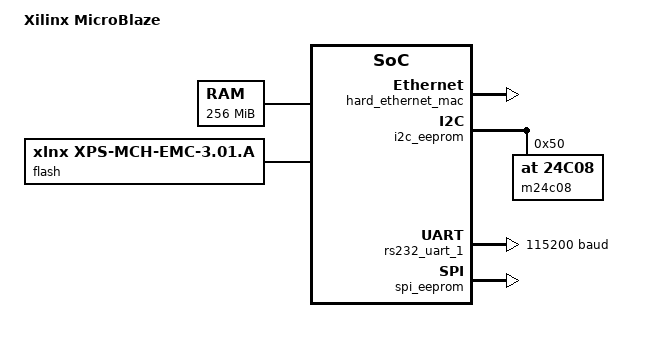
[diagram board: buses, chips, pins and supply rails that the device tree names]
/*
 * Device Tree Generator version: 1.3
 *
 * (C) Copyright 2007-2008 Xilinx, Inc.
 * (C) Copyright 2007-2009 Michal Simek
 *
 * Michal SIMEK <monstr@monstr.eu>
 *
 * This program is free software; you can redistribute it and/or
 * modify it under the terms of the GNU General Public License as
 * published by the Free Software Foundation; either version 2 of
 * the License, or (at your option) any later version.
 *
 * This program is distributed in the hope that it will be useful,
 * but WITHOUT ANY WARRANTY; without even the implied warranty of
 * MERCHANTABILITY or FITNESS FOR A PARTICULAR PURPOSE. See the
 * GNU General Public License for more details.
 *
 * You should have received a copy of the GNU General Public License
 * along with this program; if not, write to the Free Software
 * Foundation, Inc., 59 Temple Place, Suite 330, Boston,
 * MA 02111-1307 USA
 *
 * CAUTION: This file is automatically generated by libgen.
 * Version: Xilinx EDK 14.6 EDK_P.68d
 *
 * XPS project directory: linux_bsp_0
 */

/dts-v1/;
/ {
	#address-cells = <1>;
	#size-cells = <1>;
	compatible = "xlnx,microblaze";
	model = "Xilinx MicroBlaze";
	aliases {
		ethernet0 = &hard_ethernet_mac;
		serial0 = &rs232_uart_1;
	} ;
	chosen {
		bootargs = "console=ttyUL0 root=/dev/ram ip=10.1.7.250:10.1.7.125:10.1.7.2:255.255.255.0:ml505_linux:eth0
		rw mtdparts=82000000.flash:4M(bits),5M(zImage),22M(rootfs),896k(unused),128k(loader)";
		linux,stdout-path = "/plb@0/serial@81401000";
	} ;
	cpus {
		#address-cells = <1>;
		#cpus = <0x1>;
		#size-cells = <0>;
		microblaze_0: cpu@0 {
			clock-frequency = <100000000>;
			compatible = "xlnx,microblaze-8.50.b";
			d-cache-baseaddr = <0xc0000000>;
			d-cache-highaddr = <0xcfffffff>;
			d-cache-line-size = <0x10>;
			d-cache-size = <0x1000>;
			device_type = "cpu";
			i-cache-baseaddr = <0xc0000000>;
			i-cache-highaddr = <0xcfffffff>;
			i-cache-line-size = <0x10>;
			i-cache-size = <0x1000>;
			model = "microblaze,8.50.b";
			reg = <0>;
			timebase-frequency = <100000000>;
			xlnx,addr-tag-bits = <0x10>;
			xlnx,allow-dcache-wr = <0x1>;
			xlnx,allow-icache-wr = <0x1>;
			xlnx,area-optimized = <0x0>;
			xlnx,avoid-primitives = <0x0>;
			xlnx,base-vectors = <0x0>;
			xlnx,branch-target-cache-size = <0x0>;
			xlnx,cache-byte-size = <0x1000>;
			xlnx,d-axi = <0x0>;
			xlnx,d-lmb = <0x1>;
			xlnx,d-plb = <0x1>;
			xlnx,data-size = <0x20>;
			xlnx,dcache-addr-tag = <0x10>;
			xlnx,dcache-always-used = <0x1>;
			xlnx,dcache-byte-size = <0x1000>;
			xlnx,dcache-data-width = <0x0>;
			xlnx,dcache-force-tag-lutram = <0x0>;
			xlnx,dcache-interface = <0x0>;
			xlnx,dcache-line-len = <0x4>;
			xlnx,dcache-use-fsl = <0x1>;
			xlnx,dcache-use-writeback = <0x0>;
			xlnx,dcache-victims = <0x0>;
			xlnx,debug-enabled = <0x1>;
			xlnx,div-zero-exception = <0x1>;
			xlnx,dynamic-bus-sizing = <0x1>;
			xlnx,ecc-use-ce-exception = <0x0>;
			xlnx,edge-is-positive = <0x1>;
			xlnx,endianness = <0x0>;
			xlnx,family = "virtex5";
			xlnx,fault-tolerant = <0x0>;
			xlnx,fpu-exception = <0x0>;
			xlnx,freq = <0x5f5e100>;
			xlnx,fsl-data-size = <0x20>;
			xlnx,fsl-exception = <0x0>;
			xlnx,fsl-links = <0x0>;
			xlnx,i-axi = <0x0>;
			xlnx,i-lmb = <0x1>;
			xlnx,i-plb = <0x1>;
			xlnx,icache-always-used = <0x1>;
			xlnx,icache-data-width = <0x0>;
			xlnx,icache-force-tag-lutram = <0x0>;
			xlnx,icache-interface = <0x0>;
			xlnx,icache-line-len = <0x4>;
			xlnx,icache-streams = <0x1>;
			xlnx,icache-use-fsl = <0x1>;
			xlnx,icache-victims = <0x4>;
			xlnx,ill-opcode-exception = <0x1>;
			xlnx,instance = "microblaze_0";
			xlnx,interconnect = <0x1>;
			xlnx,interrupt-is-edge = <0x0>;
			xlnx,lockstep-slave = <0x0>;
			xlnx,mmu-dtlb-size = <0x4>;
			xlnx,mmu-itlb-size = <0x2>;
			xlnx,mmu-privileged-instr = <0x0>;
			xlnx,mmu-tlb-access = <0x3>;
			xlnx,mmu-zones = <0x2>;
			xlnx,number-of-pc-brk = <0x1>;
			xlnx,number-of-rd-addr-brk = <0x0>;
			xlnx,number-of-wr-addr-brk = <0x0>;
			xlnx,opcode-0x0-illegal = <0x1>;
			xlnx,optimization = <0x0>;
			xlnx,pc-width = <0x20>;
			xlnx,pvr = <0x2>;
			xlnx,pvr-user1 = <0x0>;
			xlnx,pvr-user2 = <0x0>;
			xlnx,reset-msr = <0x0>;
			xlnx,sco = <0x0>;
			xlnx,stream-interconnect = <0x0>;
			xlnx,unaligned-exceptions = <0x1>;
			xlnx,use-barrel = <0x1>;
			xlnx,use-branch-target-cache = <0x0>;
			xlnx,use-dcache = <0x1>;
			xlnx,use-div = <0x1>;
			xlnx,use-ext-brk = <0x1>;
			xlnx,use-ext-nm-brk = <0x1>;
			xlnx,use-extended-fsl-instr = <0x0>;
			xlnx,use-fpu = <0x0>;
			xlnx,use-hw-mul = <0x2>;
			xlnx,use-icache = <0x1>;
			xlnx,use-interrupt = <0x1>;
			xlnx,use-mmu = <0x3>;
			xlnx,use-msr-instr = <0x1>;
			xlnx,use-pcmp-instr = <0x1>;
			xlnx,use-reorder-instr = <0x1>;
			xlnx,use-stack-protection = <0x0>;
		} ;
	} ;
	ddr2_sdram: memory@c0000000 {
		device_type = "memory";
		reg = < 0xc0000000 0x10000000 >;
	} ;
	mb_plb: plb@0 {
		#address-cells = <1>;
		#size-cells = <1>;
		compatible = "xlnx,plb-v46-1.05.a", "xlnx,plb-v46-1.00.a", "simple-bus";
		ranges ;
		buttons_5bit: gpio@81404000 {
			compatible = "xlnx,xps-gpio-2.00.a", "xlnx,xps-gpio-1.00.a";
			interrupt-parent = <&xps_intc_0>;
			interrupts = < 11 2 >;
			reg = < 0x81404000 0x200 >;
			xlnx,all-inputs = <0x1>;
			xlnx,all-inputs-2 = <0x0>;
			xlnx,dout-default = <0x0>;
			xlnx,dout-default-2 = <0x0>;
			xlnx,family = "virtex5";
			xlnx,gpio-width = <0x5>;
			xlnx,gpio2-width = <0x20>;
			xlnx,interrupt-present = <0x1>;
			xlnx,is-dual = <0x0>;
			xlnx,tri-default = <0xffffffff>;
			xlnx,tri-default-2 = <0xffffffff>;
		} ;
		flash: flash@82000000 {
			bank-width = <2>;
			compatible = "xlnx,xps-mch-emc-3.01.a", "cfi-flash";
			reg = < 0x82000000 0x2000000 >;
			xlnx,family = "virtex5";
			xlnx,include-datawidth-matching-0 = <0x1>;
			xlnx,include-datawidth-matching-1 = <0x0>;
			xlnx,include-datawidth-matching-2 = <0x0>;
			xlnx,include-datawidth-matching-3 = <0x0>;
			xlnx,include-negedge-ioregs = <0x0>;
			xlnx,include-plb-ipif = <0x1>;
			xlnx,include-wrbuf = <0x1>;
			xlnx,max-mem-width = <0x10>;
			xlnx,mch-native-dwidth = <0x20>;
			xlnx,mch-splb-awidth = <0x20>;
			xlnx,mch-splb-clk-period-ps = <0x2710>;
			xlnx,mch0-accessbuf-depth = <0x10>;
			xlnx,mch0-protocol = <0x0>;
			xlnx,mch0-rddatabuf-depth = <0x10>;
			xlnx,mch1-accessbuf-depth = <0x10>;
			xlnx,mch1-protocol = <0x0>;
			xlnx,mch1-rddatabuf-depth = <0x10>;
			xlnx,mch2-accessbuf-depth = <0x10>;
			xlnx,mch2-protocol = <0x0>;
			xlnx,mch2-rddatabuf-depth = <0x10>;
			xlnx,mch3-accessbuf-depth = <0x10>;
			xlnx,mch3-protocol = <0x0>;
			xlnx,mch3-rddatabuf-depth = <0x10>;
			xlnx,mem0-width = <0x10>;
			xlnx,mem1-width = <0x20>;
			xlnx,mem2-width = <0x20>;
			xlnx,mem3-width = <0x20>;
			xlnx,num-banks-mem = <0x1>;
			xlnx,num-channels = <0x0>;
			xlnx,pagemode-flash-0 = <0x0>;
			xlnx,pagemode-flash-1 = <0x0>;
			xlnx,pagemode-flash-2 = <0x0>;
			xlnx,pagemode-flash-3 = <0x0>;
			xlnx,priority-mode = <0x0>;
			xlnx,synch-mem-0 = <0x0>;
			xlnx,synch-mem-1 = <0x0>;
			xlnx,synch-mem-2 = <0x0>;
			xlnx,synch-mem-3 = <0x0>;
			xlnx,synch-pipedelay-0 = <0x2>;
			xlnx,synch-pipedelay-1 = <0x2>;
			xlnx,synch-pipedelay-2 = <0x2>;
			xlnx,synch-pipedelay-3 = <0x2>;
			xlnx,tavdv-ps-mem-0 = <0x1adb0>;
			xlnx,tavdv-ps-mem-1 = <0x3a98>;
			xlnx,tavdv-ps-mem-2 = <0x3a98>;
			xlnx,tavdv-ps-mem-3 = <0x3a98>;
			xlnx,tcedv-ps-mem-0 = <0x1adb0>;
			xlnx,tcedv-ps-mem-1 = <0x3a98>;
			xlnx,tcedv-ps-mem-2 = <0x3a98>;
			xlnx,tcedv-ps-mem-3 = <0x3a98>;
			xlnx,thzce-ps-mem-0 = <0x88b8>;
			xlnx,thzce-ps-mem-1 = <0x1b58>;
			xlnx,thzce-ps-mem-2 = <0x1b58>;
			xlnx,thzce-ps-mem-3 = <0x1b58>;
			xlnx,thzoe-ps-mem-0 = <0x1b58>;
			xlnx,thzoe-ps-mem-1 = <0x1b58>;
			xlnx,thzoe-ps-mem-2 = <0x1b58>;
			xlnx,thzoe-ps-mem-3 = <0x1b58>;
			xlnx,tlzwe-ps-mem-0 = <0x88b8>;
			xlnx,tlzwe-ps-mem-1 = <0x0>;
			xlnx,tlzwe-ps-mem-2 = <0x0>;
			xlnx,tlzwe-ps-mem-3 = <0x0>;
			xlnx,tpacc-ps-flash-0 = <0x61a8>;
			xlnx,tpacc-ps-flash-1 = <0x61a8>;
			xlnx,tpacc-ps-flash-2 = <0x61a8>;
			xlnx,tpacc-ps-flash-3 = <0x61a8>;
			xlnx,twc-ps-mem-0 = <0x2af8>;
			xlnx,twc-ps-mem-1 = <0x3a98>;
			xlnx,twc-ps-mem-2 = <0x3a98>;
			xlnx,twc-ps-mem-3 = <0x3a98>;
			xlnx,twp-ps-mem-0 = <0x11170>;
			xlnx,twp-ps-mem-1 = <0x2ee0>;
			xlnx,twp-ps-mem-2 = <0x2ee0>;
			xlnx,twp-ps-mem-3 = <0x2ee0>;
			xlnx,xcl0-linesize = <0x4>;
			xlnx,xcl0-writexfer = <0x1>;
			xlnx,xcl1-linesize = <0x4>;
			xlnx,xcl1-writexfer = <0x1>;
			xlnx,xcl2-linesize = <0x4>;
			xlnx,xcl2-writexfer = <0x1>;
			xlnx,xcl3-linesize = <0x4>;
			xlnx,xcl3-writexfer = <0x1>;
		} ;
		hard_ethernet_mac: xps-ll-temac@81500000 {
			#address-cells = <1>;
			#size-cells = <1>;
			compatible = "xlnx,compound";
			ranges ;
			ethernet@81500000 {
				compatible = "xlnx,xps-ll-temac-2.03.a", "xlnx,xps-ll-temac-1.00.a";
				device_type = "network";
				interrupt-parent = <&xps_intc_0>;
				interrupts = < 9 2 >;
				llink-connected = <&PIM2>;
				local-mac-address = [ 00 0a 35 35 7b 00 ];
				reg = < 0x81500000 0x40 >;
				xlnx,avb = <0x0>;
				xlnx,bus2core-clk-ratio = <0x1>;
				xlnx,mcast-extend = <0x0>;
				xlnx,phy-type = <0x1>;
				xlnx,phyaddr = <0x1>;
				xlnx,rxcsum = <0x0>;
				xlnx,rxfifo = <0x1000>;
				xlnx,rxvlan-strp = <0x0>;
				xlnx,rxvlan-tag = <0x0>;
				xlnx,rxvlan-tran = <0x0>;
				xlnx,stats = <0x0>;
				xlnx,temac-type = <0x0>;
				xlnx,txcsum = <0x0>;
				xlnx,txfifo = <0x1000>;
				xlnx,txvlan-strp = <0x0>;
				xlnx,txvlan-tag = <0x0>;
				xlnx,txvlan-tran = <0x0>;
			} ;
		} ;
		i2c_eeprom: i2c@81406000 {
			compatible = "xlnx,xps-iic-2.03.a", "xlnx,xps-iic-2.00.a";
			interrupt-parent = <&xps_intc_0>;
			interrupts = < 10 2 >;
			reg = < 0x81406000 0x200 >;
			xlnx,clk-freq = <0x5f5e100>;
			xlnx,family = "virtex5";
			xlnx,gpo-width = <0x1>;
			xlnx,iic-freq = <0x186a0>;
			xlnx,scl-inertial-delay = <0x0>;
			xlnx,sda-inertial-delay = <0x0>;
			xlnx,ten-bit-adr = <0x0>;

      #address-cells = <1>;
      #size-cells = <0>;
      m24c08@50 {
          compatible = "at,24c08";
          reg = <0x50>;
      };
		} ;
		leds_8bit: gpio@81405000 {
			compatible = "xlnx,xps-gpio-2.00.a", "xlnx,xps-gpio-1.00.a";
			reg = < 0x81405000 0x200 >;
			xlnx,all-inputs = <0x0>;
			xlnx,all-inputs-2 = <0x0>;
			xlnx,dout-default = <0x0>;
			xlnx,dout-default-2 = <0x0>;
			xlnx,family = "virtex5";
			xlnx,gpio-width = <0x8>;
			xlnx,gpio2-width = <0x20>;
			xlnx,interrupt-present = <0x0>;
			xlnx,is-dual = <0x0>;
			xlnx,tri-default = <0xffffffff>;
			xlnx,tri-default-2 = <0xffffffff>;
		} ;
		mdm_0: debug@81408000 {
			compatible = "xlnx,mdm-2.10.a";
			reg = < 0x81408000 0x200 >;
			xlnx,family = "virtex5";
			xlnx,interconnect = <0x1>;
			xlnx,jtag-chain = <0x2>;
			xlnx,mb-dbg-ports = <0x1>;
			xlnx,use-bscan = <0x0>;
			xlnx,use-uart = <0x1>;
		} ;
		mpmc@c0000000 {
			#address-cells = <1>;
			#size-cells = <1>;
			compatible = "xlnx,mpmc-6.06.a";
			ranges ;
			PIM2: sdma@81410100 {
				compatible = "xlnx,ll-dma-1.00.a";
				interrupt-parent = <&xps_intc_0>;
				interrupts = < 5 2 4 2 >;
				reg = < 0x81410100 0x80 >;
			} ;
		} ;
		rs232_uart_1: serial@81401000 {
			clock-frequency = <100000000>;
			compatible = "xlnx,xps-uartlite-1.02.a", "xlnx,xps-uartlite-1.00.a";
			current-speed = <115200>;
			device_type = "serial";
			interrupt-parent = <&xps_intc_0>;
			interrupts = < 12 0 >;
			port-number = <0>;
			reg = < 0x81401000 0x200 >;
			xlnx,baudrate = <0x1c200>;
			xlnx,data-bits = <0x8>;
			xlnx,family = "virtex5";
			xlnx,odd-parity = <0x0>;
			xlnx,use-parity = <0x0>;
		} ;
		spi_eeprom: spi@81407000 {
			compatible = "xlnx,xps-spi-2.02.a", "xlnx,xps-spi-2.00.a";
			interrupt-parent = <&xps_intc_0>;
			interrupts = < 1 2 >;
			reg = < 0x81407000 0x200 >;
			xlnx,family = "virtex5";
			xlnx,fifo-exist = <0x1>;
			xlnx,num-ss-bits = <0x1>;
			xlnx,num-transfer-bits = <0x8>;
			xlnx,sck-ratio = <0x80>;
		} ;
		sysace_compactflash: sysace@8140c000 {
			compatible = "xlnx,xps-sysace-1.01.a", "xlnx,xps-sysace-1.00.a";
			interrupt-parent = <&xps_intc_0>;
			interrupts = < 7 2 >;
			reg = < 0x8140c000 0x200 >;
			xlnx,family = "virtex5";
			xlnx,mem-width = <0x10>;
		} ;
		xps_intc_0: interrupt-controller@81400000 {
			#interrupt-cells = <0x2>;
			compatible = "xlnx,xps-intc-2.01.a", "xlnx,xps-intc-1.00.a";
			interrupt-controller ;
			reg = < 0x81400000 0x200 >;
			xlnx,kind-of-intr = <0x1041>;
			xlnx,num-intr-inputs = <0xd>;
		} ;
		xps_ps2_0: ps2@81409000 {
			compatible = "xlnx,xps-ps2-1.01.b", "xlnx,xps-ps2-1.00.a";
			interrupt-parent = <&xps_intc_0>;
			interrupts = < 3 2 >;
			reg = < 0x81409000 0x200 >;
		} ;
		xps_ps2_1: ps2@8140a000 {
			compatible = "xlnx,xps-ps2-1.01.b", "xlnx,xps-ps2-1.00.a";
			interrupt-parent = <&xps_intc_0>;
			interrupts = < 2 2 >;
			reg = < 0x8140a000 0x200 >;
		} ;
		xps_tft_0: tft@8140b000 {
			compatible = "xlnx,xps-tft-2.01.a";
			reg = < 0x8140b000 0x200 >;
			xlnx,dcr-splb-slave-if = <0x1>;
			xlnx,default-tft-base-addr = <0xc8000000>;
			xlnx,family = "virtex5";
			xlnx,i2c-slave-addr = <0x76>;
			xlnx,mplb-awidth = <0x20>;
			xlnx,mplb-dwidth = <0x40>;
			xlnx,mplb-native-dwidth = <0x40>;
			xlnx,mplb-smallest-slave = <0x40>;
			xlnx,tft-interface = <0x1>;
		} ;
		xps_timer_0: timer@81402000 {
			compatible = "xlnx,xps-timer-1.02.a", "xlnx,xps-timer-1.00.a";
			interrupt-parent = <&xps_intc_0>;
			interrupts = < 6 0 >;
			reg = < 0x81402000 0x200 >;
			xlnx,count-width = <0x20>;
			xlnx,family = "virtex5";
			xlnx,gen0-assert = <0x1>;
			xlnx,gen1-assert = <0x1>;
			xlnx,one-timer-only = <0x0>;
			xlnx,trig0-assert = <0x1>;
			xlnx,trig1-assert = <0x1>;
		} ;
	} ;
} ;
